# qmss_qpeek register map
Vendor: Texas Instruments
Peripheral module from a debugger description file (folder Keystone2).
Registers are 32-bit, read-only, no defined reset value unless marked. A register's access mark holds for its fields unless they carry their own. Offsets are as the file gives them; lines under a group give offsets from that group; [hi:lo] are bit positions; {n}, {i} and the like mark numbered series; 'fields as' and 'values as' point back to an identical list; <NAME> marks a mode.

## QM_2_QPEEK
0x00 REG_A — (1 of 8192, stride 16)
  [18:0] queue_entry_count — This field indicates how many packets are currently queued on the queue.
0x04 REG_B — (1 of 8192, stride 16)
  [31:0] queue_byte_count — This field indicates how many bytes total are contained in all of the packets which are currently queued on this queue.
0x08 REG_C — (1 of 8192, stride 16)
  [16:0] packet_size — This field indicates the packet size of the head element of a queue.
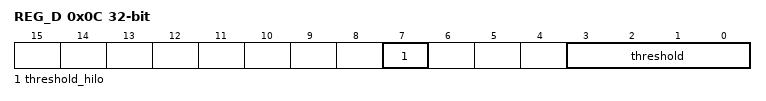
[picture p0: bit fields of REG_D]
0x0C REG_D rw — (1 of 8192, stride 16)
  [7] threshold_hilo — This field indicates whether the number of items in a queue should be greater than equal to or less than the threshold before the queue_ecnt_status\[queue\] bit is asserted.
  [3:0] threshold — This field indicates the threshold at which the queue threshold pin is asserted.
